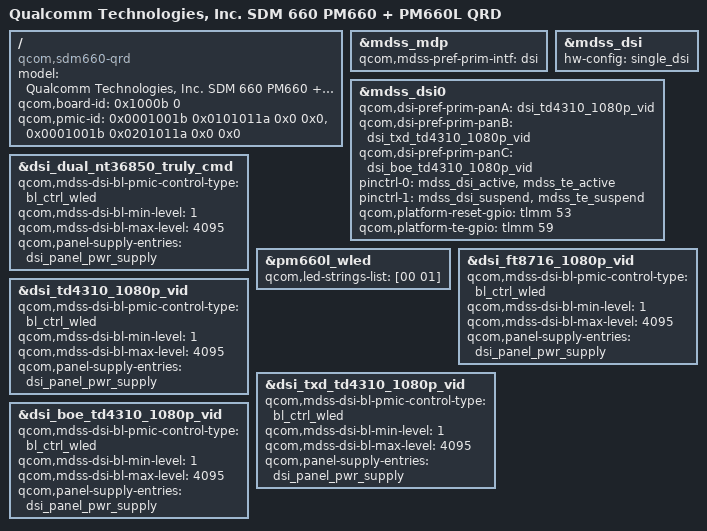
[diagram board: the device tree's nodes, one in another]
/* Copyright (c) 2016-2017, The Linux Foundation. All rights reserved.
 *
 * This program is free software; you can redistribute it and/or modify
 * it under the terms of the GNU General Public License version 2 and
 * only version 2 as published by the Free Software Foundation.
 *
 * This program is distributed in the hope that it will be useful,
 * but WITHOUT ANY WARRANTY; without even the implied warranty of
 * MERCHANTABILITY or FITNESS FOR A PARTICULAR PURPOSE.  See the
 * GNU General Public License for more details.
 */


/dts-v1/;

#include "sdm660.dtsi"
#include "sdm660-qrd.dtsi"
#include "oscar-audio.dtsi"
#include "oscar-camera.dtsi"
#include "oscar-haptics.dtsi"
#include "oscar-key.dtsi"
#include "osborn-leds.dtsi"

/ {
	model = "Qualcomm Technologies, Inc. SDM 660 PM660 + PM660L QRD";
	compatible = "qcom,sdm660-qrd", "qcom,sdm660", "qcom,qrd";
	qcom,board-id = <0x1000b 0>;
	qcom,pmic-id = <0x0001001b 0x0101011a 0x0 0x0>,
			<0x0001001b 0x0201011a 0x0 0x0>;
};

&mdss_mdp {
	qcom,mdss-pref-prim-intf = "dsi";
};
/*
&mdss_fb0 {
	qcom,mdss-mixer-swap;
};
*/
&mdss_dsi {
/*	hw-config = "split_dsi";*/
	hw-config = "single_dsi";
};

&mdss_dsi0 {
	/* qcom,dsi-pref-prim-pan = <&dsi_ft8716_1080p_vid>; */
	qcom,dsi-pref-prim-panA = <&dsi_td4310_1080p_vid>;
	qcom,dsi-pref-prim-panB = <&dsi_txd_td4310_1080p_vid>;
	qcom,dsi-pref-prim-panC = <&dsi_boe_td4310_1080p_vid>;
	pinctrl-names = "mdss_default", "mdss_sleep";
	pinctrl-0 = <&mdss_dsi_active &mdss_te_active>;
	pinctrl-1 = <&mdss_dsi_suspend &mdss_te_suspend>;
	qcom,platform-reset-gpio = <&tlmm 53 0>;
	qcom,platform-te-gpio = <&tlmm 59 0>;
};
/*
&mdss_dsi1 {
	qcom,dsi-pref-prim-pan = <&dsi_dual_nt36850_truly_cmd>;
	pinctrl-names = "mdss_default", "mdss_sleep";
	pinctrl-0 = <&mdss_dsi_active &mdss_te_active>;
	pinctrl-1 = <&mdss_dsi_suspend &mdss_te_suspend>;
	qcom,platform-reset-gpio = <&tlmm 53 0>;
	qcom,platform-te-gpio = <&tlmm 59 0>;
};
*/
&dsi_dual_nt36850_truly_cmd {
	qcom,mdss-dsi-bl-pmic-control-type = "bl_ctrl_wled";
	qcom,mdss-dsi-bl-min-level = <1>;
	qcom,mdss-dsi-bl-max-level = <4095>;
	qcom,panel-supply-entries = <&dsi_panel_pwr_supply>;
};

&pm660l_wled {
	qcom,led-strings-list = [00 01];
};

&dsi_ft8716_1080p_vid {
	qcom,mdss-dsi-bl-pmic-control-type = "bl_ctrl_wled";
	qcom,mdss-dsi-bl-min-level = <1>;
	qcom,mdss-dsi-bl-max-level = <4095>;
	qcom,panel-supply-entries = <&dsi_panel_pwr_supply>;
};

&dsi_td4310_1080p_vid {
	qcom,mdss-dsi-bl-pmic-control-type = "bl_ctrl_wled";
	qcom,mdss-dsi-bl-min-level = <1>;
	qcom,mdss-dsi-bl-max-level = <4095>;
	qcom,panel-supply-entries = <&dsi_panel_pwr_supply>;
};

&dsi_txd_td4310_1080p_vid {
	qcom,mdss-dsi-bl-pmic-control-type = "bl_ctrl_wled";
	qcom,mdss-dsi-bl-min-level = <1>;
	qcom,mdss-dsi-bl-max-level = <4095>;
	qcom,panel-supply-entries = <&dsi_panel_pwr_supply>;
};
&dsi_boe_td4310_1080p_vid {
	qcom,mdss-dsi-bl-pmic-control-type = "bl_ctrl_wled";
	qcom,mdss-dsi-bl-min-level = <1>;
	qcom,mdss-dsi-bl-max-level = <4095>;
	qcom,panel-supply-entries = <&dsi_panel_pwr_supply>;
};
